VERSION ""

NS_ :

BS_:
BU_: CAN_IO
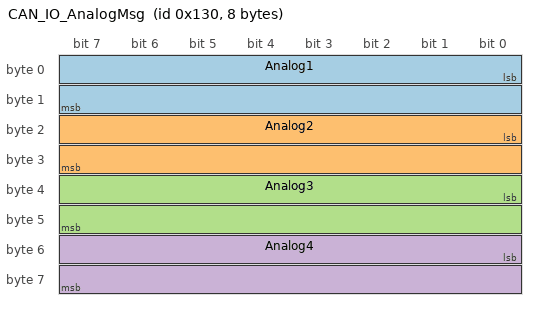
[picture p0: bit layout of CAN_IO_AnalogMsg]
BO_ 304 CAN_IO_AnalogMsg: 8 CAN_IO
   SG_ Analog1 : 0|16@1+ (1,0) [0|1] "" Vector__XXX
   SG_ Analog2 : 16|16@1+ (1,0) [0|1] "" Vector__XXX
   SG_ Analog3 : 32|16@1+ (1,0) [0|1] "" Vector__XXX
   SG_ Analog4 : 48|16@1+ (1,0) [0|1] "" Vector__XXX

BA_DEF_ BO_ "GenMsgBackgroundColor" STRING ;
BA_DEF_ BO_ "GenMsgForegroundColor" STRING ;
BA_DEF_ BO_ "filterlabeling" INT 0 0;
BA_DEF_DEF_ "GenMsgBackgroundColor" "#ffffff";
BA_DEF_DEF_ "GenMsgForegroundColor" "#232629";
BA_DEF_DEF_ "filterlabeling" 1;
